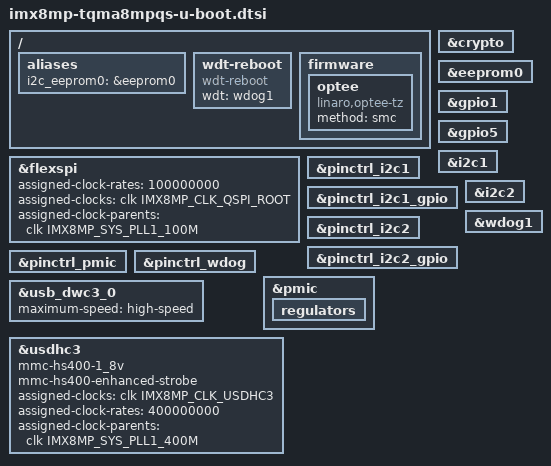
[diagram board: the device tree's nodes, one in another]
// SPDX-License-Identifier: (GPL-2.0-or-later OR MIT)
/*
 * Copyright (c) 2020-2024 TQ-Systems GmbH <u-boot@ew.tq-group.com>,
 * D-82229 Seefeld, Germany.
 */

#include "imx8mp-u-boot.dtsi"

/delete-node/ &sw_en_hog;

/ {
	aliases {
		i2c_eeprom0 = &eeprom0;
	};

	wdt-reboot {
		compatible = "wdt-reboot";
		wdt = <&wdog1>;
		bootph-pre-ram;
	};

	firmware {
		optee {
			compatible = "linaro,optee-tz";
			method = "smc";
		};
	};
};

&crypto {
	bootph-pre-ram;
};

&eeprom0 {
	bootph-pre-ram;
	/delete-property/ read-only;
	/delete-property/ vcc-supply;
};

&flexspi {
	assigned-clock-rates = <100000000>;
	assigned-clocks = <&clk IMX8MP_CLK_QSPI_ROOT>;
	assigned-clock-parents = <&clk IMX8MP_SYS_PLL1_100M>;
};

&gpio1 {
	bootph-pre-ram;
};

&gpio5 {
	bootph-pre-ram;
};

&i2c1 {
	bootph-pre-ram;
};

&pinctrl_i2c1 {
	bootph-pre-ram;
};

&pinctrl_i2c1_gpio {
	bootph-pre-ram;
};

&i2c2 {
	bootph-pre-ram;
};

&pinctrl_i2c2 {
	bootph-pre-ram;
};

&pinctrl_i2c2_gpio {
	bootph-pre-ram;
};

&pinctrl_pmic {
	bootph-pre-ram;
};

&pinctrl_wdog {
	bootph-pre-ram;
};

&pmic {
	bootph-pre-ram;

	regulators {
		bootph-pre-ram;
	};
};

&usb_dwc3_0 {
	maximum-speed = "high-speed";
};

&usdhc3 {
	mmc-hs400-1_8v;
	mmc-hs400-enhanced-strobe;
	assigned-clocks = <&clk IMX8MP_CLK_USDHC3>;
	assigned-clock-rates = <400000000>;
	assigned-clock-parents = <&clk IMX8MP_SYS_PLL1_400M>;
};

&wdog1 {
	bootph-pre-ram;
};
